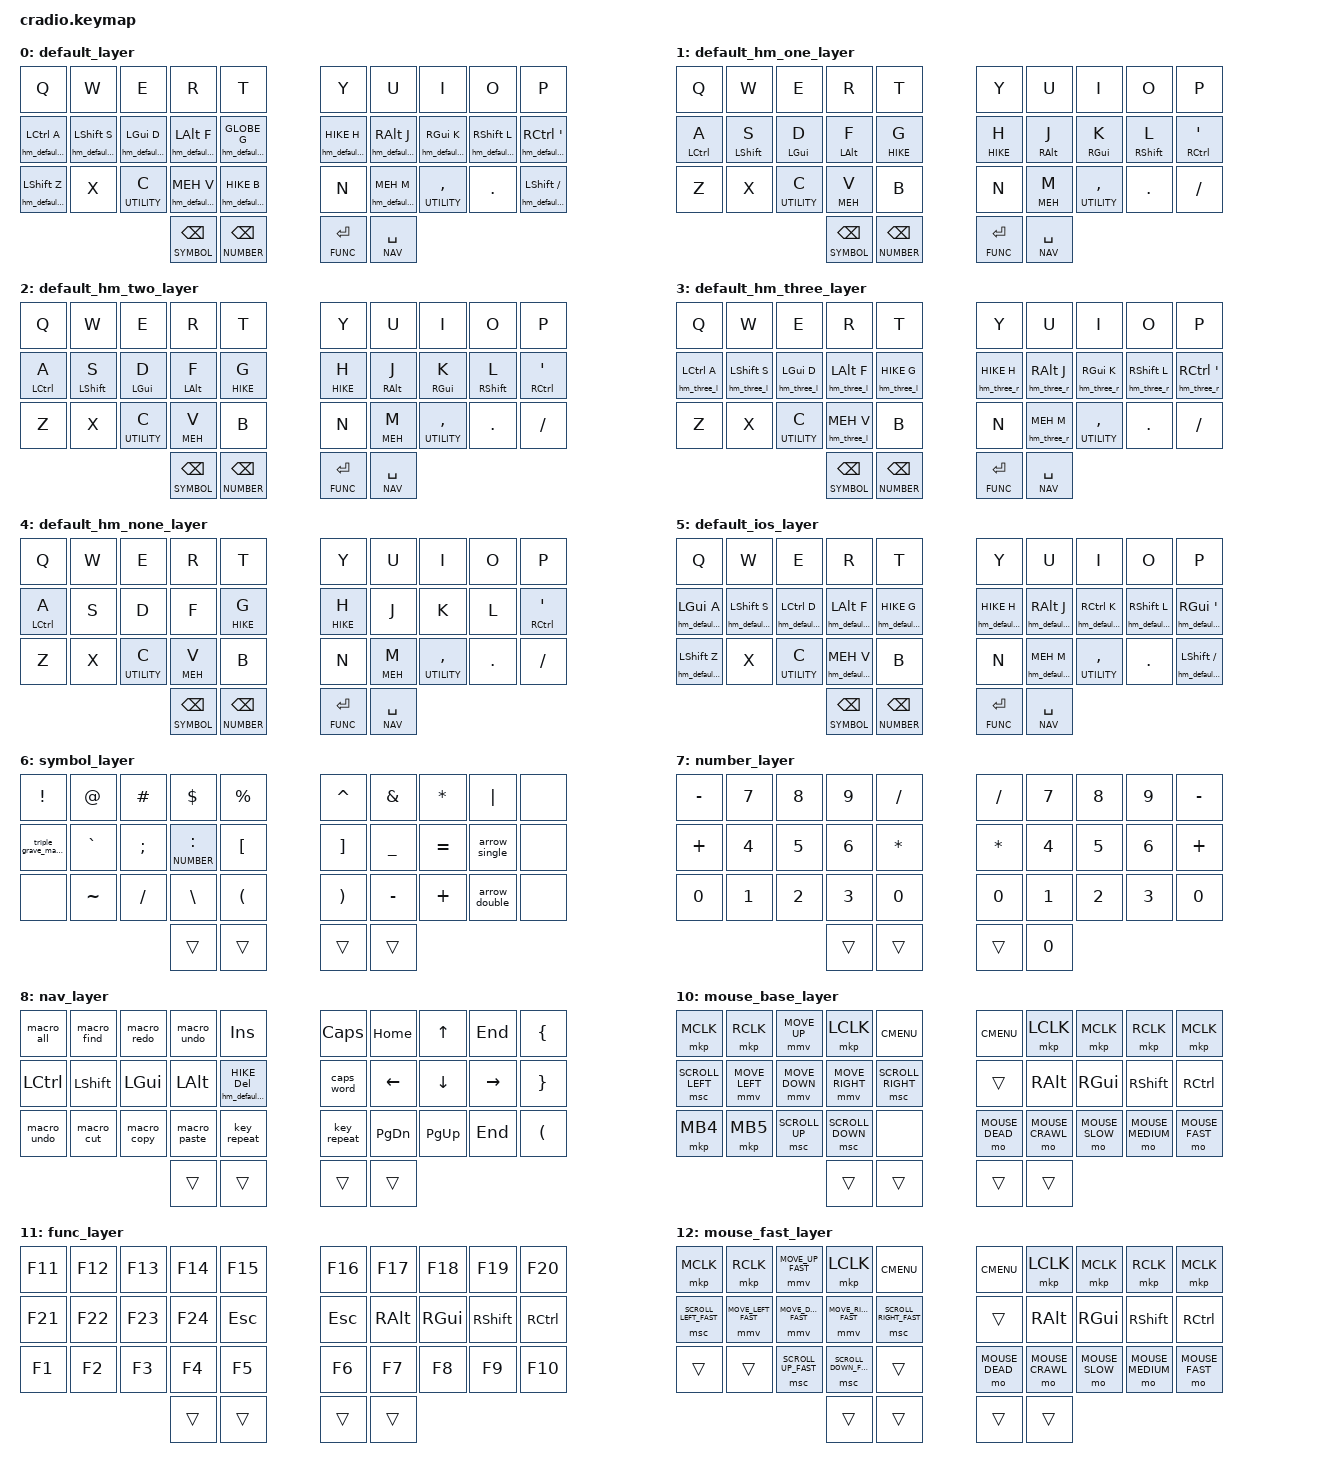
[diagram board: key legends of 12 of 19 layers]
/*
 * Copyright (c) 2020 The ZMK Contributors 
 *
 * SPDX-License-Identifier: MIT
 */

#include <behaviors.dtsi>
#include <behaviors/mouse_keys.dtsi>
#include <dt-bindings/zmk/mouse.h>
#include <dt-bindings/zmk/keys.h>
#include <dt-bindings/zmk/bt.h>
#include <dt-bindings/zmk/outputs.h>
#include <dt-bindings/zmk/ext_power.h>

#include "keymap_mouse.h"
#include "base_configs.h"




/ {
        conditional_layers {
            compatible = "zmk,conditional-layers";
            tri_layer {
                    if-layers = <SYMBOL NAV>;
                    then-layer = <MOUSE_BASE>;
            };
            
             tri_layer_two {
                     if-layers = <FUNC NAV>;
                     then-layer = <CONVENIENCE_LAYER>;
             };

             tri_layer_three {
                     if-layers = <FUNC NUMBER>;
                     then-layer = <CONVENIENCE_LAYER>;
             };
        };

        macros {
            #include "macros.dtsi"
        };
        
        combos {
            #include "combos.dtsi"
        }; 

        behaviors {
            #include "user_behaviors.dtsi"
        };

        keymap {
                compatible = "zmk,keymap";

        default_layer {										
	bindings = <									
                &kp Q                   	&kp W                   	&kp E                   	&kp R                   	&kp T                   	                        	&kp Y                   	&kp U                   	&kp I                   	&kp O                   	&kp P                   
                &hm_default_l LCTRL A   	&hm_default_l LSHFT S   	&hm_default_l LGUI D    	&hm_default_l LALT F    	&hm_default_l GLOBE G   	                        	&hm_default_r HIKE H    	&hm_default_r RALT J    	&hm_default_r RGUI K    	&hm_default_r RSHFT L   	&hm_default_r RCTRL APOS
                &hm_default_l LSHFT Z   	&kp X                   	&lt UTILITY C           	&hm_default_l MEH V     	&hm_default_l HIKE B    	                        	&kp N                   	&hm_default_r MEH M     	&lt UTILITY COMMA       	&kp DOT                 	&hm_default_r LSHFT FSLH
                                                                                                                &lt SYMBOL BSPC         	&lt NUMBER BSPC         	                        	&lt FUNC ENTER          	&lt NAV SPACE           	                        	                        	                        
                >; };										
                default_hm_one_layer {										
                        bindings = <									
                &kp Q               	&kp W               	&kp E               	&kp R               	&kp T               	                    	&kp Y               	&kp U               	&kp I               	&kp O               	&kp P               
                &hm_one_l LCTRL A   	&hm_one_l LSHFT S   	&hm_one_l LGUI D    	&hm_one_l LALT F    	&hm_one_l HIKE G    	                    	&hm_one_r HIKE H    	&hm_one_r RALT J    	&hm_one_r RGUI K    	&hm_one_r RSHFT L   	&hm_one_r RCTRL APOS
                &kp Z               	&kp X               	&lt UTILITY C       	&hm_one_l MEH V     	&kp B               	                    	&kp N               	&hm_one_r MEH M     	&lt UTILITY COMMA   	&kp DOT             	&kp FSLH            
                                                                                        &lt SYMBOL BSPC     	&lt NUMBER BSPC     	                    	&lt FUNC ENTER      	&lt NAV SPACE       	                    	                    	                    
                >; };		                        	                        	                        	                        	                        	                        	                        	                        	                        
                default_hm_two_layer {										
                        bindings = <									
                &kp Q               	&kp W               	&kp E               	&kp R               	&kp T               	                    	&kp Y               	&kp U               	&kp I               	&kp O               	&kp P               
                &hm_two_l LCTRL A   	&hm_two_l LSHFT S   	&hm_two_l LGUI D    	&hm_two_l LALT F    	&hm_two_l HIKE G    	                    	&hm_two_r HIKE H    	&hm_two_r RALT J    	&hm_two_r RGUI K    	&hm_two_r RSHFT L   	&hm_two_r RCTRL APOS
                &kp Z               	&kp X               	&lt UTILITY C       	&hm_two_l MEH V     	&kp B               	                    	&kp N               	&hm_two_r MEH M     	&lt UTILITY COMMA   	&kp DOT             	&kp FSLH            
                                                                                        &lt SYMBOL BSPC     	&lt NUMBER BSPC     	                    	&lt FUNC ENTER      	&lt NAV SPACE       	                    	                    	                    
                >; };										
                default_hm_three_layer {										
                        bindings = <									
                &kp Q                 	&kp W                 	&kp E                 	&kp R                 	&kp T                 	                      	&kp Y                 	&kp U                 	&kp I                 	&kp O                 	&kp P                 
                &hm_three_l LCTRL A   	&hm_three_l LSHFT S   	&hm_three_l LGUI D    	&hm_three_l LALT F    	&hm_three_l HIKE G    	                      	&hm_three_r HIKE H    	&hm_three_r RALT J    	&hm_three_r RGUI K    	&hm_three_r RSHFT L   	&hm_three_r RCTRL APOS
                &kp Z                 	&kp X                 	&lt UTILITY C         	&hm_three_l MEH V     	&kp B                 	                      	&kp N                 	&hm_three_r MEH M     	&lt UTILITY COMMA     	&kp DOT               	&kp FSLH              
                                                                                        &lt SYMBOL BSPC       	&lt NUMBER BSPC       	                      	&lt FUNC ENTER        	&lt NAV SPACE         	                      	                      	                      
                >; };										
                default_hm_none_layer {										
                        bindings = <									
                &kp Q                	&kp W                	&kp E                	&kp R                	&kp T                	                     	&kp Y                	&kp U                	&kp I                	&kp O                	&kp P                
                &hm_four_l LCTRL A   	&kp S                	&kp D                	&kp F                	&hm_four_l HIKE G    	                     	&hm_four_r HIKE H    	&kp J                	&kp K                	&kp L                	&hm_four_r RCTRL APOS
                &kp Z                	&kp X                	&lt UTILITY C        	&hm_four_l MEH V     	&kp B                	                     	&kp N                	&hm_four_r MEH M     	&lt UTILITY COMMA    	&kp DOT              	&kp FSLH             
                                                                                        &lt SYMBOL BSPC      	&lt NUMBER BSPC      	                     	&lt FUNC ENTER       	&lt NAV SPACE        	                     	                     	                     
                >; };										
                default_ios_layer {										
                        bindings = <									
                &kp Q                   	&kp W                   	&kp E                   	&kp R                   	&kp T                   	                        	&kp Y                   	&kp U                   	&kp I                   	&kp O                   	&kp P                   
                &hm_default_l LGUI A    	&hm_default_l LSHFT S   	&hm_default_l LCTRL D   	&hm_default_l LALT F    	&hm_default_l HIKE G    	                        	&hm_default_r HIKE H    	&hm_default_r RALT J    	&hm_default_r RCTRL K   	&hm_default_r RSHFT L   	&hm_default_r RGUI APOS 
                &hm_default_l LSHFT Z   	&kp X                   	&lt UTILITY C           	&hm_default_l MEH V     	&kp B                   	                        	&kp N                   	&hm_default_r MEH M     	&lt UTILITY COMMA       	&kp DOT                 	&hm_default_r LSHFT FSLH
                                                                                                                &lt SYMBOL BSPC         	&lt NUMBER BSPC         	                        	&lt FUNC ENTER          	&lt NAV SPACE           	                        	                        	                        
                >; };										
                symbol_layer {										
                        bindings = <									
                &kp EXCL           	&kp AT             	&kp HASH           	&kp DOLLAR         	&kp PERCENT        	                   	&kp CARET          	&kp AMPS           	&kp STAR           	&kp PIPE           	&none              
                &triple_grave_macro	&kp GRAVE          	&kp SEMI           	&lt NUMBER COLON   	&kp LBKT           	                   	&kp RBKT           	&kp UNDER          	&kp EQUAL          	&arrow_single      	&none              
                &none              	&kp TILDE          	&kp FSLH           	&kp BSLH           	&kp LPAR           	                   	&kp RPAR           	&kp MINUS          	&kp PLUS           	&arrow_double      	&none              
                                                                                        &trans             	&trans             	                   	&trans             	&trans             	                   	                   	                   
                >; };		                        	                        	                        	                        	                        	                        	                        	                        	                        
                number_layer {										
                        bindings = <									
                &kp MINUS	&kp N7   	&kp N8   	&kp N9   	&kp FSLH 	         	&kp FSLH 	&kp N7   	&kp N8   	&kp N9   	&kp MINUS
                &kp PLUS 	&kp N4   	&kp N5   	&kp N6   	&kp STAR 	         	&kp STAR 	&kp N4   	&kp N5   	&kp N6   	&kp PLUS 
                &kp N0   	&kp N1   	&kp N2   	&kp N3   	&kp N0   	         	&kp N0   	&kp N1   	&kp N2   	&kp N3   	&kp N0   
                                                                &trans   	&trans   	         	&trans   	&kp N0   	         	         	         
                >; };		                        	                        	                        	                        	                        	                        	                        	                        	                        
                nav_layer {										
                        bindings = <									
                &macro_all            	&macro_find           	&macro_redo           	&macro_undo           	&kp INS               	                      	&kp CAPS              	&kp HOME              	&kp UP                	&kp END               	&kp LBRC              
                &kp LCTRL             	&kp LSHFT             	&kp LGUI              	&kp LALT              	&hm_default_l HIKE DEL	                      	&caps_word            	&kp LEFT              	&kp DOWN              	&kp RIGHT             	&kp RBRC              
                &macro_undo           	&macro_cut            	&macro_copy           	&macro_paste          	&key_repeat           	                      	&key_repeat           	&kp PG_DN             	&kp PG_UP             	&kp END               	&kp LPAR              
                                                                                        &trans                	&trans                	                      	&trans                	&trans                	                      	                      	                      
                >; };		                        	                        	                        	                        	                        	                        	                        	                        	                        
                util_layer {										
                        bindings = <									
                &macro_go_ios_zero                  	&macro_go_ios_one                   	&macro_go_windows_zero              	&macro_go_windows_one               	&out OUT_USB                        	                                    	&soft_off                           	&kp C_BRI_DN                        	&kp C_BRI_UP                        	&ext_power EP_OFF                   	&ext_power EP_ON                    
                &macro_go_ios_two                   	&macro_go_ios_three                 	&macro_go_windows_two               	&macro_go_windows_three             	&out OUT_BLE                        	                                    	&kp C_PLAY_PAUSE                    	&kp C_PREV                          	&kp C_NEXT                          	&kp C_RW                            	&kp C_FF                            
                &macro_go_ios_four                  	&lt LAYER_CHANGER &macro_go_ios_five	&macro_go_windows_four              	&macro_go_windows_five              	&bt BT_CLR                          	                                    	&kp C_MUTE                          	&kp C_VOLUME_DOWN                   	&kp C_VOLUME_UP                     	&lt LAYER_CHANGER C_MUTE            	&trans                              
                                                                                                                                        &trans                              	&trans                              	                                    	&trans                              	&trans                              	                                    	                                    	                                    
                >; };										
                mouse_base_layer {										
                        bindings = <									
                &mkp MCLK        	&mkp RCLK        	&mmv MOVE_UP     	&mkp LCLK        	&kp K_CMENU      	                 	&kp K_CMENU      	&mkp LCLK        	&mkp MCLK        	&mkp RCLK        	&mkp MCLK        
                &msc SCROLL_LEFT 	&mmv MOVE_LEFT   	&mmv MOVE_DOWN   	&mmv MOVE_RIGHT  	&msc SCROLL_RIGHT	                 	&trans           	&kp RALT         	&kp RGUI         	&kp RSHFT        	&kp RCTRL        
                &mkp MB4         	&mkp MB5         	&msc SCROLL_UP   	&msc SCROLL_DOWN 	&none            	                 	&mo MOUSE_DEAD   	&mo MOUSE_CRAWL  	&mo MOUSE_SLOW   	&mo MOUSE_MEDIUM 	&mo MOUSE_FAST   
                                                                                        &trans           	&trans           	                 	&trans           	&trans           	                 	                 	                 
                >; };										
                func_layer {										
                        bindings = <									
                &kp F11  	&kp F12  	&kp F13  	&kp F14  	&kp F15  	         	&kp F16  	&kp F17  	&kp F18  	&kp F19  	&kp F20  
                &kp F21  	&kp F22  	&kp F23  	&kp F24  	&kp ESC  	         	&kp ESC  	&kp RALT 	&kp RGUI 	&kp RSHFT	&kp RCTRL
                &kp F1   	&kp F2   	&kp F3   	&kp F4   	&kp F5   	         	&kp F6   	&kp F7   	&kp F8   	&kp F9   	&kp F10  
                                                                &trans   	&trans   	         	&trans   	&trans   	         	         	         
                >; };										
                mouse_fast_layer {										
                        bindings = <									
                &mkp MCLK             	&mkp RCLK             	&mmv MOVE_UP_FAST     	&mkp LCLK             	&kp K_CMENU           	                      	&kp K_CMENU           	&mkp LCLK             	&mkp MCLK             	&mkp RCLK             	&mkp MCLK             
                &msc SCROLL_LEFT_FAST 	&mmv MOVE_LEFT_FAST   	&mmv MOVE_DOWN_FAST   	&mmv MOVE_RIGHT_FAST  	&msc SCROLL_RIGHT_FAST	                      	&trans                	&kp RALT              	&kp RGUI              	&kp RSHFT             	&kp RCTRL             
                &trans                	&trans                	&msc SCROLL_UP_FAST   	&msc SCROLL_DOWN_FAST 	&trans                	                      	&mo MOUSE_DEAD        	&mo MOUSE_CRAWL       	&mo MOUSE_SLOW        	&mo MOUSE_MEDIUM      	&mo MOUSE_FAST        
                                                                                        &trans                	&trans                	                      	&trans                	&trans                	                      	                      	                      
                >; };										
                mouse_med_layer {										
                        bindings = <									
                &mkp MCLK               	&mkp RCLK               	&mmv MOVE_UP_MEDIUM     	&mkp LCLK               	&kp K_CMENU             	                        	&kp K_CMENU             	&mkp LCLK               	&mkp MCLK               	&mkp RCLK               	&mkp MCLK               
                &msc SCROLL_LEFT_MEDIUM 	&mmv MOVE_LEFT_MEDIUM   	&mmv MOVE_DOWN_MEDIUM   	&mmv MOVE_RIGHT_MEDIUM  	&msc SCROLL_RIGHT_MEDIUM	                        	&trans                  	&kp RALT                	&kp RGUI                	&kp RSHFT               	&kp RCTRL               
                &trans                  	&trans                  	&msc SCROLL_UP_MEDIUM   	&msc SCROLL_DOWN_MEDIUM 	&trans                  	                        	&mo MOUSE_DEAD          	&mo MOUSE_CRAWL         	&mo MOUSE_SLOW          	&mo MOUSE_MEDIUM        	&mo MOUSE_FAST          
                                                                                                                &trans                  	&trans                  	                        	&trans                  	&trans                  	                        	                        	                        
                >; };										
                mouse_slow_layer {										
                        bindings = <									
                &mkp MCLK             	&mkp RCLK             	&mmv MOVE_UP_SLOW     	&mkp LCLK             	&kp K_CMENU           	                      	&kp K_CMENU           	&mkp LCLK             	&mkp MCLK             	&mkp RCLK             	&mkp MCLK             
                &msc SCROLL_LEFT_SLOW 	&mmv MOVE_LEFT_SLOW   	&mmv MOVE_DOWN_SLOW   	&mmv MOVE_RIGHT_SLOW  	&msc SCROLL_RIGHT_SLOW	                      	&trans                	&kp RALT              	&kp RGUI              	&kp RSHFT             	&kp RCTRL             
                &trans                	&trans                	&msc SCROLL_UP_SLOW   	&msc SCROLL_DOWN_SLOW 	&trans                	                      	&mo MOUSE_DEAD        	&mo MOUSE_CRAWL       	&mo MOUSE_SLOW        	&mo MOUSE_MEDIUM      	&mo MOUSE_FAST        
                                                                                        &trans                	&trans                	                      	&trans                	&trans                	                      	                      	                      
                >; };										
                mouse_crawl_layer {										
                        bindings = <									
                &mkp MCLK              	&mkp RCLK              	&mmv MOVE_UP_CRAWL     	&mkp LCLK              	&kp K_CMENU            	                       	&kp K_CMENU            	&mkp LCLK              	&mkp MCLK              	&mkp RCLK              	&mkp MCLK              
                &msc SCROLL_LEFT_CRAWL 	&mmv MOVE_LEFT_CRAWL   	&mmv MOVE_DOWN_CRAWL   	&mmv MOVE_RIGHT_CRAWL  	&msc SCROLL_RIGHT_CRAWL	                       	&trans                 	&kp RALT               	&kp RGUI               	&kp RSHFT              	&kp RCTRL              
                &trans                 	&trans                 	&msc SCROLL_UP_CRAWL   	&msc SCROLL_DOWN_CRAWL 	&trans                 	                       	&mo MOUSE_DEAD         	&mo MOUSE_CRAWL        	&mo MOUSE_SLOW         	&mo MOUSE_MEDIUM       	&mo MOUSE_FAST         
                                                                                        &trans                 	&trans                 	                       	&trans                 	&trans                 	                       	                       	                       
                >; };										
                mouse_dead_layer {										
                        bindings = <									
                &mkp MCLK              	&mkp RCLK              	&mmv MOVE_UP_CRAWL     	&mkp LCLK              	&kp K_CMENU            	                       	&kp K_CMENU            	&mkp LCLK              	&mkp MCLK              	&mkp RCLK              	&mkp MCLK              
                &msc SCROLL_LEFT_CRAWL 	&mmv MOVE_LEFT_CRAWL   	&mmv MOVE_DOWN_CRAWL   	&mmv MOVE_RIGHT_CRAWL  	&msc SCROLL_RIGHT_CRAWL	                       	&trans                 	&kp RALT               	&kp RGUI               	&kp RSHFT              	&kp RCTRL              
                &trans                 	&trans                 	&msc SCROLL_UP_CRAWL   	&msc SCROLL_DOWN_CRAWL 	&trans                 	                       	&mo MOUSE_DEAD         	&mo MOUSE_CRAWL        	&mo MOUSE_SLOW         	&mo MOUSE_MEDIUM       	&mo MOUSE_FAST         
                                                                                        &trans                 	&trans                 	                       	&trans                 	&trans                 	                       	                       	                       
                >; };										
                convenience_layer {										
                        bindings = <									
                &none                  	&none                  	&none                  	&git_branch            	&git_add               	                       	&git_add_i_hunk        	&surround_brace        	&surround_paran        	&surround_bracket      	&none                  
                &git_clean_n           	&git_diff_cached       	&git_reflog            	&git_status            	&git_commit            	                       	&git_commit_amend      	&macro_jira_issue      	&none                  	&none                  	&none                  
                &none                  	&none                  	&git_merged_list       	&git_no_merged_list    	&git_push              	                       	&git_checkout_switch   	&git_branch_commit_list	&none                  	&none                  	&none                  
                                                                                        &trans                 	&trans                 	                       	&trans                 	&trans                 	                       	                       	                       
                >; };										
                layer_changer_layer {										
                        bindings = <									
                &none               	&none               	&to DEFAULT_HM_TWO  	&to DEFAULT_HM_ONE  	&to DEFAULT_HM      	                    	&none               	&none               	&none               	&none               	&none               
                &none               	&none               	&to DEFAULT_HM_NONE 	&to DEFAULT_HM_THREE	&to DEFAULT_IOS     	                    	&none               	&none               	&none               	&none               	&none               
                &none               	&none               	&none               	&none               	&none               	                    	&none               	&none               	&none               	&none               	&none               
                                                                                        &trans              	&trans              	                    	&trans              	&trans              	                    	                    	                    
                >; };										


        };
 };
